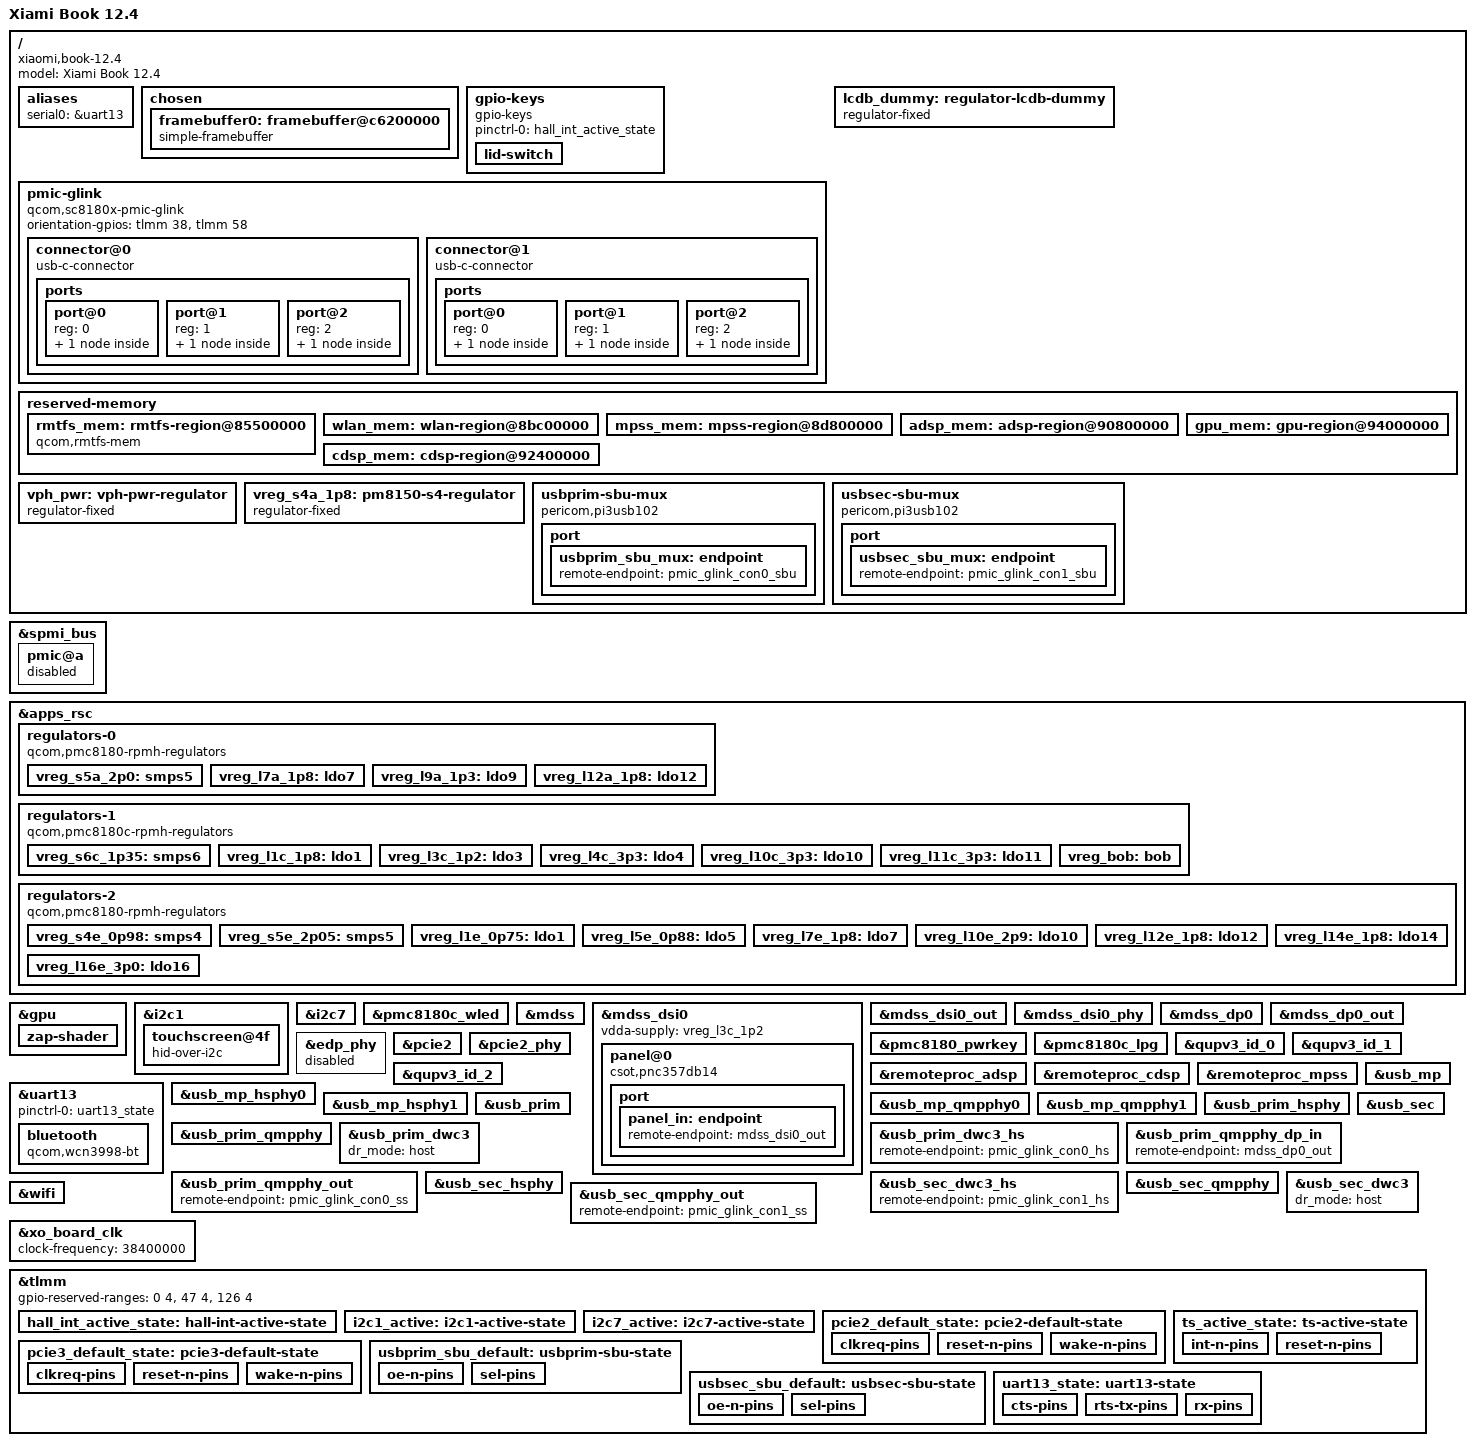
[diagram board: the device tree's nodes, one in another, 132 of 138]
// SPDX-License-Identifier: BSD-3-Clause
/*
 * Based on:
 % - sc8180x-primus.dts
 % - sc8180x-lenovo-flex-5g.dts
 */

/dts-v1/;

#include <dt-bindings/firmware/qcom,scm.h>
#include <dt-bindings/gpio/gpio.h>
#include <dt-bindings/input/gpio-keys.h>
#include <dt-bindings/input/input.h>
#include <dt-bindings/regulator/qcom,rpmh-regulator.h>
#include "sc8180x.dtsi"
#include "sc8180x-pmics.dtsi"

/ {
	model = "Xiami Book 12.4";
	compatible = "xiaomi,book-12.4", "qcom,sc8180x";

	aliases {
		serial0 = &uart13;
	};

	chosen {
		#address-cells = <2>;
		#size-cells = <2>;
		ranges;
        
        // From UEFI Memory Map
        // 0x80600000, 0x02400000, "Display Reserved",  AddMem, MEM_RES, SYS_MEM_CAP, Reserv, WRITE_THROUGH_XN
		framebuffer0: framebuffer@c6200000 {
			compatible = "simple-framebuffer";
			reg = <0x0 0x80600000 0x0 0x02400000>;
			width = <1600>;
			height = <2560>;
			stride = <(1600 * 4)>;
			format = "a8r8g8b8";
		};
	};

	gpio-keys {
		compatible = "gpio-keys";

		pinctrl-0 = <&hall_int_active_state>;
		pinctrl-names = "default";

		lid-switch {
			gpios = <&tlmm 121 GPIO_ACTIVE_LOW>;
			linux,input-type = <EV_SW>;
			linux,code = <SW_LID>;
			wakeup-source;
			wakeup-event-action = <EV_ACT_DEASSERTED>;
		};
	};

	pmic-glink {
		compatible = "qcom,sc8180x-pmic-glink", "qcom,pmic-glink";

		#address-cells = <1>;
		#size-cells = <0>;
		orientation-gpios = <&tlmm 38 GPIO_ACTIVE_HIGH>,
				    <&tlmm 58 GPIO_ACTIVE_HIGH>;

		connector@0 {
			compatible = "usb-c-connector";
			reg = <0>;
			power-role = "dual";
			data-role = "dual";

			ports {
				#address-cells = <1>;
				#size-cells = <0>;

				port@0 {
					reg = <0>;

					pmic_glink_con0_hs: endpoint {
						remote-endpoint = <&usb_prim_dwc3_hs>;
					};
				};

				port@1 {
					reg = <1>;

					pmic_glink_con0_ss: endpoint {
						remote-endpoint = <&usb_prim_qmpphy_out>;
					};
				};

				port@2 {
					reg = <2>;

					pmic_glink_con0_sbu: endpoint {
						remote-endpoint = <&usbprim_sbu_mux>;
					};
				};
			};
		};

		connector@1 {
			compatible = "usb-c-connector";
			reg = <1>;
			power-role = "dual";
			data-role = "dual";

			ports {
				#address-cells = <1>;
				#size-cells = <0>;
				port@0 {
					reg = <0>;

					pmic_glink_con1_hs: endpoint {
						remote-endpoint = <&usb_sec_dwc3_hs>;
					};
				};

				port@1 {
					reg = <1>;

					pmic_glink_con1_ss: endpoint {
						remote-endpoint = <&usb_sec_qmpphy_out>;
					};
				};

				port@2 {
					reg = <2>;

					pmic_glink_con1_sbu: endpoint {
						remote-endpoint = <&usbsec_sbu_mux>;
					};
				};
			};
		};
	};

	lcdb_dummy: regulator-lcdb-dummy {
		compatible = "regulator-fixed";
		regulator-name = "lcdb_dummy";
		regulator-min-microvolt = <5500000>;
		regulator-max-microvolt = <5500000>;
	};

	reserved-memory {
		// Based on Windows Memory Map
		// 0x85d00000 ++ 0x200000     RMTFS
		// 0x8b700000 ++ 0x500000     CAMERA
		// 0x8bc00000 ++ 0x180000     WLAN
		// 0x8d800000 ++ 0x3000000    MPSS
		// 0x90800000 ++ 0x1c00000    ADSP
		// 0x92400000 ++ 0x800000     CDSP
		// 0x92c00000 ++ 0x1400000    SPSS/SLPI
		// 0x94000000 ++ 0x5000       GPU
		// 0x9a500000 ++ 0x600000     QSM

		// USE REGION: MPSS_EFS (FULL)
		rmtfs_mem: rmtfs-region@85500000 {
			compatible = "qcom,rmtfs-mem";
			reg = <0x0 0x85500000 0x0 0x200000>;
			no-map;

			qcom,client-id = <1>;
			qcom,vmid = <QCOM_SCM_VMID_MSS_MSA>;
		};

		wlan_mem: wlan-region@8bc00000 {
			reg = <0x0 0x8bc00000 0x0 0x180000>;
			no-map;
		};

		mpss_mem: mpss-region@8d800000 {
			reg = <0x0 0x8d800000 0x0 0x3000000>;
			no-map;
		};

		adsp_mem: adsp-region@90800000 {
			reg = <0x0 0x90800000 0x0 0x1c00000>;
			no-map;
		};

		cdsp_mem: cdsp-region@92400000 {
			reg = <0x0 0x92400000 0x0 0x800000>;
			no-map;
		};

		gpu_mem: gpu-region@94000000 {
			reg = <0x0 0x94000000 0x0 0x5000>;
			no-map;
		};
	};

	vph_pwr: vph-pwr-regulator {
		compatible = "regulator-fixed";
		regulator-name = "vph_pwr";
		regulator-min-microvolt = <3700000>;
		regulator-max-microvolt = <3700000>;
	};

	vreg_s4a_1p8: pm8150-s4-regulator {
		compatible = "regulator-fixed";
		regulator-name = "vreg_s4a_1p8";

		regulator-min-microvolt = <1800000>;
		regulator-max-microvolt = <1800000>;

		regulator-always-on;
		regulator-boot-on;

		vin-supply = <&vph_pwr>;
	};

	usbprim-sbu-mux {
		compatible = "pericom,pi3usb102", "gpio-sbu-mux";

		enable-gpios = <&tlmm 152 GPIO_ACTIVE_LOW>;
		select-gpios = <&tlmm 100 GPIO_ACTIVE_HIGH>;

		pinctrl-names = "default";
		pinctrl-0 = <&usbprim_sbu_default>;

		mode-switch;
		orientation-switch;

		port {
			usbprim_sbu_mux: endpoint {
				remote-endpoint = <&pmic_glink_con0_sbu>;
			};
		};
	};

	usbsec-sbu-mux {
		compatible = "pericom,pi3usb102", "gpio-sbu-mux";

		enable-gpios = <&tlmm 188 GPIO_ACTIVE_LOW>;
		select-gpios = <&tlmm 187 GPIO_ACTIVE_HIGH>;

		pinctrl-names = "default";
		pinctrl-0 = <&usbsec_sbu_default>;

		mode-switch;
		orientation-switch;

		port {
			usbsec_sbu_mux: endpoint {
				remote-endpoint = <&pmic_glink_con1_sbu>;
			};
		};
	};
};

&spmi_bus {
	pmic@a {
        status = "disabled";
    };
};

&apps_rsc {
	regulators-0 {
		compatible = "qcom,pmc8180-rpmh-regulators";
		qcom,pmic-id = "a";

		vdd-s5-supply = <&vph_pwr>;
		vdd-l7-l12-l14-l15-supply = <&vreg_s5a_2p0>;

		vreg_s5a_2p0: smps5 {
			regulator-min-microvolt = <2040000>;
			regulator-max-microvolt = <2100000>;
		};

		vreg_l7a_1p8: ldo7 {
			regulator-min-microvolt = <1800000>;
			regulator-max-microvolt = <1800000>;
			regulator-initial-mode = <RPMH_REGULATOR_MODE_HPM>;
		};

		vreg_l9a_1p3: ldo9 {
			regulator-min-microvolt = <1296000>;
			regulator-max-microvolt = <1304000>;
			regulator-initial-mode = <RPMH_REGULATOR_MODE_HPM>;
		};

		vreg_l12a_1p8: ldo12 {
			regulator-min-microvolt = <1800000>;
			regulator-max-microvolt = <1800000>;
			regulator-initial-mode = <RPMH_REGULATOR_MODE_HPM>;
		};
	};

	regulators-1 {
		compatible = "qcom,pmc8180c-rpmh-regulators";
		qcom,pmic-id = "c";

		vdd-s6-supply = <&vph_pwr>;
		vdd-l2-l3-supply = <&vreg_s6c_1p35>;
		vdd-bob-supply = <&vph_pwr>;

		vreg_s6c_1p35: smps6 {
			regulator-min-microvolt = <1350000>;
			regulator-max-microvolt = <1372000>;
			regulator-initial-mode = <RPMH_REGULATOR_MODE_HPM>;
		};

		vreg_l1c_1p8: ldo1 {
			regulator-min-microvolt = <1800000>;
			regulator-max-microvolt = <1800000>;
			regulator-initial-mode = <RPMH_REGULATOR_MODE_HPM>;
		};

		vreg_l3c_1p2: ldo3 {
			regulator-min-microvolt = <1200000>;
			regulator-max-microvolt = <1200000>;
			regulator-initial-mode = <RPMH_REGULATOR_MODE_HPM>;
		};

		vreg_l4c_3p3: ldo4 {
			regulator-min-microvolt = <3008000>;
			regulator-max-microvolt = <3008000>;
			regulator-initial-mode = <RPMH_REGULATOR_MODE_HPM>;
		};

		vreg_l10c_3p3: ldo10 {
			regulator-min-microvolt = <3000000>;
			regulator-max-microvolt = <3312000>;
			regulator-initial-mode = <RPMH_REGULATOR_MODE_HPM>;
		};

		vreg_l11c_3p3: ldo11 {
			regulator-min-microvolt = <3296000>;
			regulator-max-microvolt = <3304000>;
			regulator-initial-mode = <RPMH_REGULATOR_MODE_HPM>;
		};

		vreg_bob: bob {
			regulator-min-microvolt = <3296000>;
			regulator-max-microvolt = <3350000>;
			regulator-initial-mode = <RPMH_REGULATOR_MODE_HPM>;
		};
	};

	regulators-2 {
		compatible = "qcom,pmc8180-rpmh-regulators";
		qcom,pmic-id = "e";

		vdd-s4-supply = <&vph_pwr>;
		vdd-s5-supply = <&vph_pwr>;
		vdd-l2-l10-supply = <&vreg_bob>;
		vdd-l3-l4-l5-l18-supply = <&vreg_s4e_0p98>;
		vdd-l7-l12-l14-l15-supply = <&vreg_s5e_2p05>;
		vdd-l13-l16-l17-supply = <&vreg_bob>;

		vreg_s4e_0p98: smps4 {
			regulator-min-microvolt = <992000>;
			regulator-max-microvolt = <992000>;
			regulator-initial-mode = <RPMH_REGULATOR_MODE_HPM>;
		};

		vreg_s5e_2p05: smps5 {
			regulator-min-microvolt = <2040000>;
			regulator-max-microvolt = <2040000>;
			regulator-initial-mode = <RPMH_REGULATOR_MODE_HPM>;
		};

		vreg_l1e_0p75: ldo1 {
			regulator-min-microvolt = <752000>;
			regulator-max-microvolt = <752000>;
			regulator-initial-mode = <RPMH_REGULATOR_MODE_HPM>;
		};

		vreg_l5e_0p88: ldo5 {
			regulator-min-microvolt = <880000>;
			regulator-max-microvolt = <880000>;
			regulator-initial-mode = <RPMH_REGULATOR_MODE_HPM>;
		};

		vreg_l7e_1p8: ldo7 {
			regulator-min-microvolt = <1800000>;
			regulator-max-microvolt = <1800000>;
			regulator-initial-mode = <RPMH_REGULATOR_MODE_HPM>;
			regulator-allowed-modes = <RPMH_REGULATOR_MODE_LPM
						   RPMH_REGULATOR_MODE_HPM>;
			regulator-allow-set-load;
		};

		vreg_l10e_2p9: ldo10 {
			regulator-min-microvolt = <2904000>;
			regulator-max-microvolt = <2904000>;
			regulator-initial-mode = <RPMH_REGULATOR_MODE_HPM>;
			regulator-allowed-modes = <RPMH_REGULATOR_MODE_LPM
						   RPMH_REGULATOR_MODE_HPM>;
			regulator-allow-set-load;
		};

		vreg_l12e_1p8: ldo12 {
			regulator-min-microvolt = <1800000>;
			regulator-max-microvolt = <1800000>;
			regulator-initial-mode = <RPMH_REGULATOR_MODE_HPM>;
		};

		vreg_l14e_1p8: ldo14 {
			regulator-min-microvolt = <1800000>;
			regulator-max-microvolt = <1800000>;
			regulator-initial-mode = <RPMH_REGULATOR_MODE_HPM>;

			regulator-boot-on;
			regulator-always-on;
		};

		vreg_l16e_3p0: ldo16 {
			regulator-min-microvolt = <3072000>;
			regulator-max-microvolt = <3072000>;
			regulator-initial-mode = <RPMH_REGULATOR_MODE_HPM>;
		};
	};
};

&gpu {
	status = "okay";

	zap-shader {
		memory-region = <&gpu_mem>;
		firmware-name = "qcom/sc8180x/XIAOMI/A51/qcdxkmsuc8180.mbn";
	};
};

&i2c1 {
	clock-frequency = <100000>;

	pinctrl-0 = <&i2c1_active>;
	pinctrl-names = "default";

	status = "okay";

    // Based on DSDT
    // Device (TSC1), Method _CRS
	// Name (LPXC, Package (0x01)
	touchscreen@4f {
		compatible = "hid-over-i2c";
		reg = <0x4f>;
		hid-descr-addr = <0x1>;

		vdd-supply = <&vreg_l4c_3p3>;
		vddl-supply = <&vreg_l12e_1p8>;
		post-power-on-delay-ms = <200>;

		interrupts-extended = <&tlmm 122 IRQ_TYPE_LEVEL_LOW>;

		pinctrl-names = "default";
		pinctrl-0 = <&ts_active_state>;
	};
};

&i2c7 {
	clock-frequency = <1000000>;

	pinctrl-0 = <&i2c7_active>;
	pinctrl-names = "default";

	status = "okay";

    // Charger
    // Device (SXB), Method _CRS
    // No driver is provided for this device currently
    /*
    txra9530@3b {
        compatible = "wingtech,txra9530";
        reg = <0x3b>;

        interrupt-parent = <&tlmm>;
        interrupts-extended = <&tlmm 101 IRQ_TYPE_LEVEL_LOW>,
                             <&tlmm 189 IRQ_TYPE_EDGE_LOW>,
                             <&tlmm 97 IRQ_TYPE_EDGE_LOW>;

        gpios = <&tlmm 11 GPIO_ACTIVE_LOW>,
                <&tlmm 186 GPIO_ACTIVE_LOW>;

        pinctrl-0 = <&txra9530_int_default>;
        pinctrl-names = "default";

        status = "okay";
    };
    */
};

// From PNC357DB1.xml
// FIXME: Due to PEP0 defination, device is using PMIC-WLED
// 		  backlight, need to confirm the configuration.
// FIXME: The units may be wrong. Need to be verified
&pmc8180c_wled {
    qcom,switching-freq = <1920>;
    // From PNC357DB1-4 Datasheet:
    // LED Light Bar Power Supply Current: {
    //     "Symbol": "LED_K(1-8)",
    //     "Value": { "Typ": 140 },
    //     "Unit": "mA"
    // }
    qcom,num-strings = <2>;
    qcom,current-limit-microamp = <17500>;
    qcom,cabc;

    status = "okay";
};

&mdss {
	status = "okay";
};

&mdss_dsi0 {
    status = "okay";
	vdda-supply = <&vreg_l3c_1p2>;

    panel@0 {
        compatible = "csot,pnc357db14";
        reg = <0>;
		vdd1-supply = <&vreg_l1c_1p8>;
		vsn-supply = <&lcdb_dummy>;
		vsp-supply = <&lcdb_dummy>;

		backlight = <&pmc8180c_wled>;
		// There are two GPIOs defined in ACPI (GPU0)
		// GPIO 190: DSI Panel Reset
		// GPIO 6: DSI Mode Select
        reset-gpios = <&tlmm 190 GPIO_ACTIVE_LOW>;

        port {
            panel_in: endpoint {
                remote-endpoint = <&mdss_dsi0_out>;
            };
        };
    };
};

&mdss_dsi0_out {
    data-lanes = <0 1 2 3>;
    remote-endpoint = <&panel_in>;
};

&mdss_dsi0_phy {
    status = "okay";
};

&mdss_dp0 {
	status = "okay";
};

&mdss_dp0_out {
	data-lanes = <0 1>;
	remote-endpoint = <&usb_prim_qmpphy_dp_in>;
};

// Device don't support eDP
&edp_phy {
	status = "disabled";
};

// Both PCIE2 and PCIE3 is dectected on Windows,
// Lets enable them.

// FIXME: Unknown Pin for PCIE2
&pcie2 {
	perst-gpios = <&tlmm 102 GPIO_ACTIVE_LOW>;
	wake-gpios = <&tlmm 104 GPIO_ACTIVE_HIGH>;

	//vddpe-3v3-supply = <&vreg_nvme_3p3>;

	num-lanes = <2>;

	pinctrl-names = "default";
	pinctrl-0 = <&pcie2_default_state>;

	status = "okay";
};

&pcie2_phy {
	vdda-phy-supply = <&vreg_l5e_0p88>;
	vdda-pll-supply = <&vreg_l3c_1p2>;

	status = "okay";
};

&pmc8180_pwrkey {
	status = "okay";
};

&pmc8180c_lpg {
	status = "okay";
};

&qupv3_id_0 {
	status = "okay";
};

&qupv3_id_1 {
	status = "okay";
};

&qupv3_id_2 {
	status = "okay";
};

&remoteproc_adsp {
	memory-region = <&adsp_mem>;
	firmware-name = "qcom/sc8180x/XIAOMI/A51/qcadsp8180.mbn";

	status = "okay";
};

&remoteproc_cdsp {
	memory-region = <&cdsp_mem>;
	firmware-name = "qcom/sc8180x/XIAOMI/A51/qccdsp8180.mbn";

	status = "okay";
};

&remoteproc_mpss {
	memory-region = <&mpss_mem>;
	firmware-name = "qcom/sc8180x/XIAOMI/A51/qcmpss8180_nm.mbn";

	status = "okay";
};

&uart13 {
	pinctrl-0 = <&uart13_state>;
	pinctrl-names = "default";

	status = "okay";

	bluetooth {
		compatible = "qcom,wcn3998-bt";

		vddio-supply = <&vreg_s4a_1p8>;
		vddxo-supply = <&vreg_l7a_1p8>;
		vddrf-supply = <&vreg_l9a_1p3>;
		vddch0-supply = <&vreg_l11c_3p3>;
		max-speed = <3200000>;
	};
};

&usb_mp {
	status = "okay";
};

&usb_mp_hsphy0 {
	vdda-pll-supply = <&vreg_l5e_0p88>;
	vdda18-supply = <&vreg_l12a_1p8>;
	vdda33-supply = <&vreg_l16e_3p0>;

	status = "okay";
};

&usb_mp_hsphy1 {
	vdda-pll-supply = <&vreg_l5e_0p88>;
	vdda18-supply = <&vreg_l12a_1p8>;
	vdda33-supply = <&vreg_l16e_3p0>;

	status = "okay";
};

&usb_mp_qmpphy0 {
	vdda-phy-supply = <&vreg_l3c_1p2>;
	vdda-pll-supply = <&vreg_l5e_0p88>;

	status = "okay";
};

&usb_mp_qmpphy1 {
	vdda-phy-supply = <&vreg_l3c_1p2>;
	vdda-pll-supply = <&vreg_l5e_0p88>;

	status = "okay";
};

&usb_prim_hsphy {
	vdda-pll-supply = <&vreg_l5e_0p88>;
	vdda18-supply = <&vreg_l12a_1p8>;
	vdda33-supply = <&vreg_l16e_3p0>;

	status = "okay";
};

&usb_prim_qmpphy {
	vdda-phy-supply = <&vreg_l3c_1p2>;
	vdda-pll-supply = <&vreg_l5e_0p88>;

	orientation-switch;

	status = "okay";
};

&usb_prim {
	status = "okay";
};

&usb_prim_dwc3 {
	dr_mode = "host";
};

&usb_prim_dwc3_hs {
	remote-endpoint = <&pmic_glink_con0_hs>;
};

&usb_prim_qmpphy_dp_in {
	remote-endpoint = <&mdss_dp0_out>;
};

&usb_prim_qmpphy_out {
	remote-endpoint = <&pmic_glink_con0_ss>;
};

&usb_sec_dwc3_hs {
	remote-endpoint = <&pmic_glink_con1_hs>;
};

&usb_sec_hsphy {
	vdda-pll-supply = <&vreg_l5e_0p88>;
	vdda18-supply = <&vreg_l12a_1p8>;
	vdda33-supply = <&vreg_l16e_3p0>;

	status = "okay";
};

&usb_sec_qmpphy {
	vdda-phy-supply = <&vreg_l3c_1p2>;
	vdda-pll-supply = <&vreg_l5e_0p88>;

	orientation-switch;

	status = "okay";
};

&usb_sec_qmpphy_out {
	remote-endpoint = <&pmic_glink_con1_ss>;
};

&usb_sec {
	status = "okay";
};

&usb_sec_dwc3 {
	dr_mode = "host";
};

&wifi {
	memory-region = <&wlan_mem>;

	vdd-0.8-cx-mx-supply = <&vreg_l1e_0p75>;
	vdd-1.8-xo-supply = <&vreg_l7a_1p8>;
	vdd-1.3-rfa-supply = <&vreg_l9a_1p3>;
	vdd-3.3-ch0-supply = <&vreg_l11c_3p3>;
	vdd-3.3-ch1-supply = <&vreg_l10c_3p3>;

	status = "okay";
};

&xo_board_clk {
	clock-frequency = <38400000>;
};

&tlmm {
	gpio-reserved-ranges = <0 4>, <47 4>, <126 4>;

	hall_int_active_state: hall-int-active-state {
		pins = "gpio121";
		function = "gpio";

		bias-disable;
	};

	i2c1_active: i2c1-active-state {
		pins = "gpio114", "gpio115";
		function = "qup1";

		bias-pull-up = <1>;
		drive-strength = <2>;
	};

	i2c7_active: i2c7-active-state {
		pins = "gpio98", "gpio99";
		function = "qup7";

		bias-pull-up;
		drive-strength = <2>;
	};

	pcie2_default_state: pcie2-default-state {
		clkreq-pins {
			pins = "gpio176";
			function = "pci_e2";
			bias-pull-up;
		};

		reset-n-pins {
			pins = "gpio102";
			function = "gpio";

			drive-strength = <2>;
			output-low;
			bias-pull-down;
		};

		wake-n-pins {
			pins = "gpio104";
			function = "gpio";

			drive-strength = <2>;
			bias-pull-up;
		};
	};

	pcie3_default_state: pcie3-default-state {
		clkreq-pins {
			pins = "gpio179";
			function = "pci_e3";
			bias-pull-up;
		};

		reset-n-pins {
			pins = "gpio178";
			function = "gpio";

			drive-strength = <2>;
			output-low;
			bias-pull-down;
		};

		wake-n-pins {
			pins = "gpio180";
			function = "gpio";

			drive-strength = <2>;
			bias-pull-up;
		};
	};

	ts_active_state: ts-active-state {
		int-n-pins {
			pins = "gpio122";
			function = "gpio";

			bias-pull-up;
			drive-strength = <2>;
		};

		reset-n-pins {
			pins = "gpio54";
			function = "gpio";

			bias-pull-up;
			drive-strength = <2>;
		};
	};

	usbprim_sbu_default: usbprim-sbu-state {
		oe-n-pins {
			pins = "gpio152";
			function = "gpio";
			bias-disable;
			drive-strength = <16>;
			output-high;
		};

		sel-pins {
			pins = "gpio100";
			function = "gpio";
			bias-disable;
			drive-strength = <16>;
		};
	};

	usbsec_sbu_default: usbsec-sbu-state {
		oe-n-pins {
			pins = "gpio188";
			function = "gpio";
			bias-disable;
			drive-strength = <16>;
			output-high;
		};

		sel-pins {
			pins = "gpio187";
			function = "gpio";
			bias-disable;
			drive-strength = <16>;
		};
	};

	uart13_state: uart13-state {
		cts-pins {
			pins = "gpio43";
			function = "qup13";
			bias-pull-down;
		};

		rts-tx-pins {
			pins = "gpio44", "gpio45";
			function = "qup13";
			drive-strength = <2>;
			bias-disable;
		};

		rx-pins {
			pins = "gpio46";
			function = "qup13";
			bias-pull-up;
		};
	};
};
